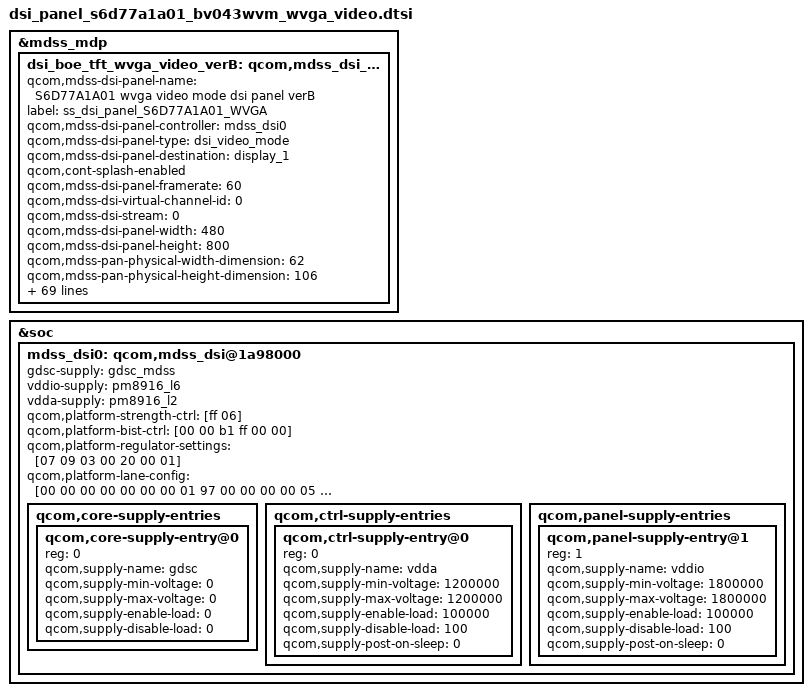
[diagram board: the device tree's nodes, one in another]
/* Copyright (c) 2013-14, Samsung Electronics Corporation. All rights reserved.
 *
 * This program is free software; you can redistribute it and/or modify
 * it under the terms of the GNU General Public License version 2 and
 * only version 2 as published by the Free Software Foundation.
 *
 * This program is distributed in the hope that it will be useful,
 * but WITHOUT ANY WARRANTY; without even the implied warranty of
 * MERCHANTABILITY or FITNESS FOR A PARTICULAR PURPOSE.  See the
 * GNU General Public License for more details.
 */

/*---------------------------------------------------------------------------
 * This file is autogenerated file using gcdb parser. Please do not edit it.
 * Update input XML file to add a new entry or update variable in this file
 * VERSION = "1.0"
 *---------------------------------------------------------------------------*/
&mdss_mdp {
	dsi_boe_tft_wvga_video_verB: qcom,mdss_dsi_S6D77A1A01_bv043wvm_wvga_video {
		qcom,mdss-dsi-panel-name = "S6D77A1A01 wvga video mode dsi panel verB";
		label = "ss_dsi_panel_S6D77A1A01_WVGA";
		qcom,mdss-dsi-panel-controller = <&mdss_dsi0>;
		qcom,mdss-dsi-panel-type = "dsi_video_mode";
		qcom,mdss-dsi-panel-destination = "display_1";
		qcom,cont-splash-enabled;
		qcom,mdss-dsi-panel-framerate = <60>;
		qcom,mdss-dsi-virtual-channel-id = <0>;
		qcom,mdss-dsi-stream = <0>;
		qcom,mdss-dsi-panel-width = <480>;
		qcom,mdss-dsi-panel-height = <800>;
		qcom,mdss-pan-physical-width-dimension = <62>; /* <Width> real size of panel in mm */
		qcom,mdss-pan-physical-height-dimension = <106>; /*<Height> real size of panel in mm */
		qcom,mdss-dsi-lp11-init;
		qcom,mdss-dsi-init-delay-us = <100>;
		qcom,mdss-dsi-h-front-porch = <84>;
		qcom,mdss-dsi-h-back-porch = <90>;
		qcom,mdss-dsi-h-pulse-width = <40>;
		qcom,mdss-dsi-h-sync-skew = <0>;
		qcom,mdss-dsi-v-back-porch = <12>;
		qcom,mdss-dsi-v-front-porch = <16>;
		qcom,mdss-dsi-v-pulse-width = <4>;
		qcom,mdss-dsi-h-left-border = <0>;
		qcom,mdss-dsi-h-right-border = <0>;
		qcom,mdss-dsi-v-top-border = <0>;
		qcom,mdss-dsi-v-bottom-border = <0>;
		qcom,mdss-dsi-bpp = <24>;
		qcom,mdss-dsi-color-order = <0>;
		qcom,mdss-dsi-underflow-color = <0xff>;
		qcom,mdss-dsi-border-color = <0>;
		qcom,mdss-dsi-dma-trigger = "trigger_sw";
		qcom,mdss-dsi-mdp-trigger = "none";
		qcom,mdss-dsi-bl-min-level = <1>;
		qcom,mdss-dsi-bl-max-level = <255>;
		qcom,mdss-dsi-bl-pmic-control-type = "bl_ctrl_dcs";
		qcom,mdss-dsi-lane-0-state;
		qcom,mdss-dsi-lane-1-state;
		qcom,mdss-dsi-bllp-eof-power-mode;
		qcom,mdss-dsi-bllp-power-mode;
		qcom,mdss-dsi-traffic-mode = "burst_mode";
		qcom,mdss-force-clk-lane-hs = <0>;
		qcom,mdss-dsi-reset-sequence = <1 20>, <0 1>, <1 20>;
		qcom,mdss-dsi-h-sync-pulse = <0>;
		qcom,mdss-dsi-panel-timings = [79 1A 10 00 3E 40 16 1C 0F 03 04 00];
		qcom,mdss-dsi-t-clk-pre = <0x15>;
		qcom,mdss-dsi-t-clk-post = <0x04>;
		qcom,mdss-dsi-on-command = [
					/* < Power Setting Sequence(1) > */
					39 01 00 00 00 00 03 F0 5A 5A
					39 01 00 00 00 00 03 FC A5 A5

					39 01 00 00 00 00 02 B3 01
					39 01 00 00 00 00 02 B5 10
					39 01 00 00 00 00 04 BC 00 29 51

					39 01 00 00 00 00 03 E3 24 2C

					39 01 00 00 00 00 01 21

					39 01 00 00 00 00 08 F2 11 04 08 10 10 82 54
					39 01 00 00 00 00 06 F3 91 00 00 00 10
					39 01 00 00 00 00 2C F4 01 02 23 24 25 25 26 26 29 29 2C 2B 2C 07 08 05 04 04 01 01 22 0A 17 0F 11 23 0D 0A 0B 02 19 13 1E 1F 23 20 05 16 1A 16 1E 24 1E
					39 01 00 00 00 00 1D F5 5A 62 B9 21 35 55 06 08 00 39 00 00 0B 4B C4 CB 4B 12 12 1A 00 10 E0 E2 0E 34 34 03
					39 01 00 00 00 00 12 FE 00 02 01 39 60 40 21 00 4B 00 80 00 F0 00 00 00 02

                    /*<Initializing Sequence (2)>*/
					39 01 00 00 00 00 0B EE 86 00 86 00 00 00 00 00 00 00
					39 01 00 00 00 00 16 EF 34 12 00 00 0A 29 08 27 21 40 10 28 02 21 21 03 03 40 00 00 00
					39 01 00 00 00 00 1F F7 02 1B 1A 00 01 0D 0D 09 09 0C 0C 08 08 04 06 02 1B 1A 00 01 0F 0F 0B 0B 0E 0E 0A 0A 05 07
					39 01 00 00 00 00 07 F6 63 25 15 00 00 2E
					39 01 00 00 00 00 02 36 10

					/* gamma setting*/
					39 01 00 00 00 00 12 FA 00 3F 09 10 08 0D 12 12 12 18 1B 1B 1D 1E 21 25 2D
					39 01 00 00 00 00 12 FB 00 3F 09 11 08 0E 13 12 13 19 1B 1C 1D 1E 21 25 2D
					/* gamma setting*/

					/*<power setting sequence(1-2)>*/
					39 01 00 00 00 00 03 FC 5A 5A

					/* < Display on Sequence> */
					05 01 00 00 78 00 02 11 00
					05 01 00 00 0A 00 02 29 00
					39 01 00 00 00 00 06 C0 57 01 4C 41 20              //pwm

					39 01 00 00 00 00 02 55 01
					39 01 00 00 00 00 02 53 24
					];
		qcom,mdss-dsi-on-command-state = "dsi_lp_mode";
		qcom,mdss-dsi-off-command-state = "dsi_hs_mode";
		qcom,mdss-dsi-off-command = [39 01 00 10  00 02 28 00
					39 01 00 00 46 00 02 10 00];
		samsung,tft-common-support;
		samsung,panel-vendor = "BOE";
		samsung,mdss-dsi-bl-scale-low-level = <8>;
		samsung,mdss-dsi-bl-scale-dim-level = <8>;
		samsung,mdss-dsi-bl-scale-default-level = <89>;
		samsung,mdss-dsi-bl-scale-max-level = <188>;
		samsung,mdss-dsi-bl-pms-low-level = <7>;
		samsung,mdss-dsi-bl-pms-dim-level = <7>;
		samsung,mdss-dsi-bl-pms-default-level = <158>;
		samsung,mdss-dsi-bl-pms-max-level = <255>;
/*
 * ************************************************************************************************************************************
 *
 *
 *			Below  parameters are samsung dependent thigs
 *
 *
 * ************************************************************************************************************************************
 */
		samsung,packet_size_tx_cmds_revA = [
			37 01 00 00 00 00 02 07 00
		];
		/*
		 * First parameters can be changed
		 * by function of samsung_nv_read()
		 * because of that means offset of
		 * read position
		 */		
		samsung,reg_read_pos_tx_cmds_revA = [
			15 01 00 00 00 00 02 B0 00
		];
		samsung,manufacture_id0_rx_cmds_revA = [06 01 00 00 00 00 01 da 03 00];
		samsung,manufacture_id1_rx_cmds_revA = [06 01 00 00 00 00 01 db 03 00];
		samsung,manufacture_id2_rx_cmds_revA = [06 01 00 00 00 00 01 dc 03 00];
/*
		* Command sets for CABC control
*/
		samsung,tft_pwm_tx_cmds_revA=[
			39 01 00 00 00 00 02 51 FF/*First command should be PWM duty change command*/
		];
		samsung,cabc_on_tx_cmds_revA = [
			39 01 00 00 00 00 02 55 01
		];
		samsung,cabc_off_tx_cmds_revA = [
			39 01 00 00 00 00 02 55 00
		];
		/*
		* ************************************************************************************************************************
		* Scaled level to index mappings
		* ************************************************************************************************************************
		*/
	//for j1_vzw
	samsung,scaled_level_map_table_revA = <
		/*<idx>	  <from>  <till> <scaled_level> */
			0		0		7		1
			1		8		9		3
			2		10		12		5
			3		13		14		7
			4		15		17		10
			5		18		19		13
			6		20		22		16
			7		23		24		19
			8		25		27		21
			9		28		29		23
			10		30		32		26
			11		33		34		29
			12		35		37		32
			13		38		39		35
			14		40		42		38
			15		43		44		41
			16		45		47		44
			17		48		49		47
			18		50		52		50
			19		53		54		53
			20		55		57		56
			21		58		59		59
			22		60		62		62
			23		63		64		65
			24		65		67		68
			25		68		70		71
			26		71		72		75
			27		73		75		77
			28		76		77		79
			29		78		80		81
			30		81		82		83
			31		83		85		85
			32		86		87		87
			33		88		90		89
			34		91		92		91
			35		93		95		93
			36		96		97		95
			37		98		100		97
			38		101		102		100
			39		103		105		103
			40		106		107		106
			41		108		110		110
			42		111		112		113
			43		113		115		116
			44		116		117		117
			45		118		120		118
			46		121		122		119
			47		123		125		120
			48		126		127		121
			49		128		130		122
			50		131		133		123
			51		134		135		124
			52		136		138		125
			53		139		140		126
			54		141		143		127
			55		144		145		129
			56		146		148		130
			57		149		150		131
			58		151		153		132
			59		154		155		133
			60		156		158		135
			61		159		160		137
			62		161		163		139
			63		164		165		140
			64		166		168		141
			65		169		170		143
			66		171		173		145
			67		174		175		147
			68		176		178		149
			69		179		180		150
			70		181		183		152
			71		184		185		153
			72		186		188		154
			72		189		190		155
			74		191		193		156
			75		194		196		157
			76		197		198		158
			77		199		201		159
			78		202		203		160
			79		204		206		162
			80		207		208		164
			81		209		211		165  
			82		212		213		166
			83		214		216		167
			84		217		218		169
			85		219		221		171
			86		222		223		173
			87		224		226		175
			88		227		228		177
			89		229		231		178
			90		232		233		179
			91		234		236		181
			92		237		238		183
			93		239		241		188
			94		242		243		191
			95		244		246		195
			96		247		248		198
			97		249		251		201
			98		252		253		204
			99		254		255		208
		>;
	};
};
&soc {
	mdss_dsi0: qcom,mdss_dsi@1a98000 {
		gdsc-supply = <&gdsc_mdss>;
		vddio-supply = <&pm8916_l6>;
		vdda-supply = <&pm8916_l2>;
		qcom,platform-strength-ctrl = [ff 06];
		qcom,platform-bist-ctrl = [00 00 b1 ff 00 00];
		qcom,platform-regulator-settings = [07 09 03 00 20 00 01];
		qcom,platform-lane-config = [00 00 00 00 00 00 00 01 97
			00 00 00 00 05 00 00 01 97
			00 00 00 00 0a 00 00 01 97
			00 00 00 00 0f 00 00 01 97
			00 c0 00 00 00 00 00 01 bb];
		qcom,core-supply-entries {
			#address-cells = <1>;
			#size-cells = <0>;

			qcom,core-supply-entry@0 {
				reg = <0>;
				qcom,supply-name = "gdsc";
				qcom,supply-min-voltage = <0>;
				qcom,supply-max-voltage = <0>;
				qcom,supply-enable-load = <0>;
				qcom,supply-disable-load = <0>;
			};
		};
		qcom,ctrl-supply-entries {
			#address-cells = <1>;
			#size-cells = <0>;

			qcom,ctrl-supply-entry@0 {
				reg = <0>;
				qcom,supply-name = "vdda";
				qcom,supply-min-voltage = <1200000>;
				qcom,supply-max-voltage = <1200000>;
				qcom,supply-enable-load = <100000>;
				qcom,supply-disable-load = <100>;
				qcom,supply-post-on-sleep = <0>;
			};
		};
		qcom,panel-supply-entries {
			#address-cells = <1>;
			#size-cells = <0>;

			qcom,panel-supply-entry@1 {
				reg = <1>;
				qcom,supply-name = "vddio";
				qcom,supply-min-voltage = <1800000>;
				qcom,supply-max-voltage = <1800000>;
				qcom,supply-enable-load = <100000>;
				qcom,supply-disable-load = <100>;
				qcom,supply-post-on-sleep = <0>;
			};
		};
	};
};

